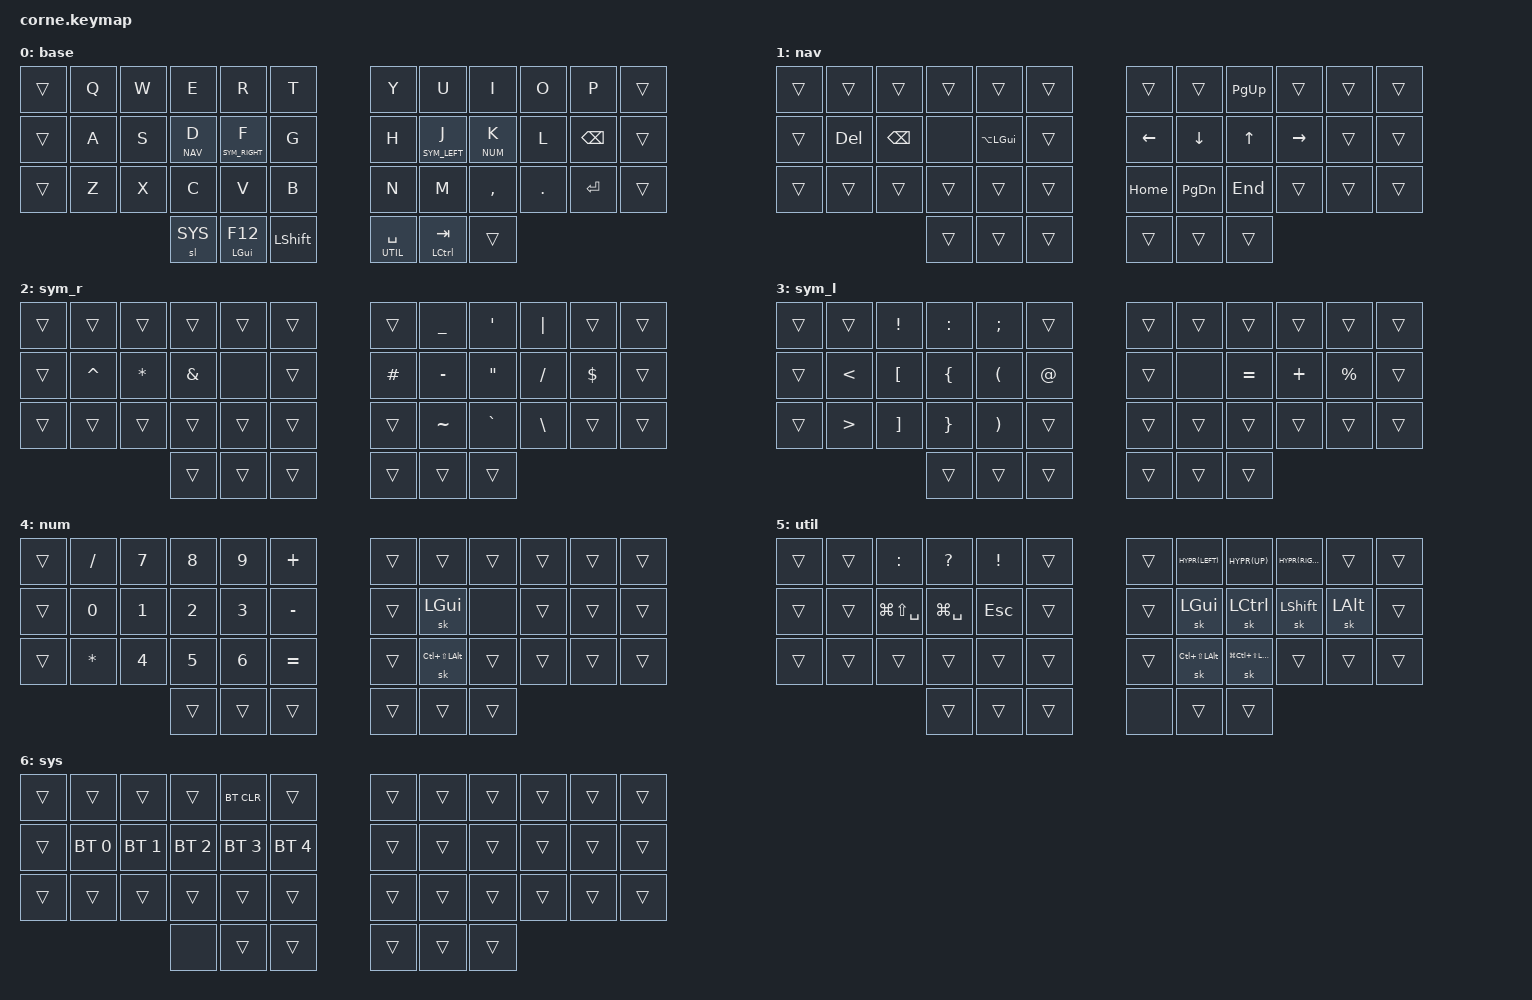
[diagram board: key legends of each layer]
/*
 * Copyright (c) 2020 The ZMK Contributors
 *
 * SPDX-License-Identifier: MIT
 */

#include <behaviors.dtsi>
#include <dt-bindings/zmk/keys.h>
#include <dt-bindings/zmk/bt.h>
#include <dt-bindings/zmk/outputs.h>

// Layer definitions
#define BASE 0
#define NAV 1
#define SYM_RIGHT 2
#define SYM_LEFT 3
#define NUM 4
#define UTIL 5
#define SYS 6

#define QUICK_TAP_MS 175

// QMK-like keycodes
#define _XXX &none
#define ____ &trans

#define _HYPR(kc) &kp LC(LS(LA(LG(kc))))
#define _MEH(kc) &kp LC(LS(LA(kc)))

#define _RAYCAST &kp LG(SPACE)
#define _1PASS &kp LG(LS(SPACE))

// Sticky mods - named explicitly here because I forget what they're are
#define _SK_MEH &sk LC(LS(LALT))
#define _SK_HYPR &sk LG(LC(LS(LALT)))

&mt {
  flavor = "balanced";
  tapping-term-ms = <280>;
  quick-tap-ms = <QUICK_TAP_MS>;
  global-quick-tap;
};

&sk {
  release-after-ms = <900>;
  quick-release;
};

&lt {
  flavor = "balanced";
  tapping-term-ms = <200>;
  quick-tap-ms = <QUICK_TAP_MS>;
};

/ {
	combos {
		compatible = "zmk,combos";

		// both right thumb keys
		combo_sys {
			timeout-ms = <200>;
			key-positions = <39 40>;
			bindings = <&mo SYS>;
		};
		// left index and middle finger
		combo_esc {
			timeout-ms = <50>;
			key-positions = <15 16>;
			bindings = <&kp ESC>;
		};
		// left middle and ring finger one row down
		combo_hypr_l {
			timeout-ms = <50>;
			key-positions = <26 27>;
			bindings = <&kp LG(LC(LS(LALT)))>;
		};
		// left index and middle finger one row down
		combo_meh_l {
			timeout-ms = <50>;
			key-positions = <27 28>;
			bindings = <&kp LC(LS(LALT))>;
		};
		// right index and middle finger one row down
		combo_meh_r {
			timeout-ms = <50>;
			key-positions = <31 32>;
			bindings = <&kp LC(LS(LALT))>;
		};
		// right middle and ring finger one row down
		combo_hypr_r {
			timeout-ms = <50>;
			key-positions = <32 33>;
			bindings = <&kp LG(LC(LS(LALT)))>;
		};
	};

  keymap {
    compatible = "zmk,keymap";

    base {
      display-name = "base";
      bindings = <
//        ┌──────┬───┬───┬──────────┬───────────────┬──────┐                        ┌───────────────┬───────────────┬──────────┬───┬──────┬──────┐
//        │ ____ │ Q │ W │    E     │       R       │  T   │                        │       Y       │       U       │    I     │ O │  P   │ ____ │
//        ├──────┼───┼───┼──────────┼───────────────┼──────┤                        ├───────────────┼───────────────┼──────────┼───┼──────┼──────┤
//        │ ____ │ A │ S │ lt NAV D │ lt SYM_rght F │  G   │                        │       H       │ lt SYM_left J │ lt NUM K │ L │ bspc │ ____ │
//        ├──────┼───┼───┼──────────┼───────────────┼──────┤                        ├───────────────┼───────────────┼──────────┼───┼──────┼──────┤
//        │ ____ │ Z │ X │    C     │       V       │  B   │                        │       N       │       M       │    ,     │ . │ ent  │ ____ │
//        └──────┴───┴───┴──────────┼───────────────┼──────┼──────┐   ┌─────────────┼───────────────┼───────────────┼──────────┴───┴──────┴──────┘
//                                  │    sl SYS     │ lgui │ lsft │   │ lt UTIL spc │ mt lctlTL tab │     ____      │
//                                  └───────────────┴──────┴──────┘   └─────────────┴───────────────┴───────────────┘
      ____   &kp Q   &kp W   &kp E       &kp R             &kp T                                        &kp Y          &kp U            &kp I       &kp O     &kp P       ____
      ____   &kp A   &kp S   &lt NAV D   &lt SYM_RIGHT F   &kp G                                        &kp H          &lt SYM_LEFT J   &lt NUM K   &kp L     &kp BSPC    ____
      ____   &kp Z   &kp X   &kp C       &kp V             &kp B                                        &kp N          &kp M            &kp COMMA   &kp DOT   &kp ENTER   ____
                                         &sl SYS           &mt LGUI F12   &kp LSHIFT       &lt UTIL SPACE   &mt LCTL TAB   ____
      >;
    };

    nav {
      display-name = "nav";
      bindings = <
//        ┌──────┬──────┬──────┬──────┬────────────┬──────┐                 ┌──────┬──────┬──────┬──────┬──────┬──────┐
//        │ ____ │ ____ │ ____ │ ____ │    ____    │ ____ │                 │ ____ │ ____ │ pgup │ ____ │ ____ │ ____ │
//        ├──────┼──────┼──────┼──────┼────────────┼──────┤                 ├──────┼──────┼──────┼──────┼──────┼──────┤
//        │ ____ │ del  │ bspc │ _XXX │ lalt(lgui) │ ____ │                 │ left │ down │  up  │ rght │ ____ │ ____ │
//        ├──────┼──────┼──────┼──────┼────────────┼──────┤                 ├──────┼──────┼──────┼──────┼──────┼──────┤
//        │ ____ │ ____ │ ____ │ ____ │    ____    │ ____ │                 │ home │ pgdn │ end  │ ____ │ ____ │ ____ │
//        └──────┴──────┴──────┴──────┼────────────┼──────┼──────┐   ┌──────┼──────┼──────┼──────┴──────┴──────┴──────┘
//                                    │    ____    │ ____ │ ____ │   │ ____ │ ____ │ ____ │
//                                    └────────────┴──────┴──────┘   └──────┴──────┴──────┘
      ____   ____      ____       ____   ____           ____                     ____       ____        &kp PG_UP   ____        ____   ____
      ____   &kp DEL   &kp BSPC   _XXX   &kp LA(LGUI)   ____                     &kp LEFT   &kp DOWN    &kp UP      &kp RIGHT   ____   ____
      ____   ____      ____       ____   ____           ____                     &kp HOME   &kp PG_DN   &kp END     ____        ____   ____
                                         ____           ____   ____       ____   ____       ____
      >;
    };

    sym_right {
      display-name = "sym_r";
      bindings = <
//        ┌──────┬──────┬──────┬──────┬──────┬──────┐                 ┌──────┬──────┬───┬───┬──────┬──────┐
//        │ ____ │ ____ │ ____ │ ____ │ ____ │ ____ │                 │ ____ │  _   │ ' │ | │ ____ │ ____ │
//        ├──────┼──────┼──────┼──────┼──────┼──────┤                 ├──────┼──────┼───┼───┼──────┼──────┤
//        │ ____ │  ^   │  *   │  &   │ _XXX │ ____ │                 │  #   │  -   │ " │ / │  $   │ ____ │
//        ├──────┼──────┼──────┼──────┼──────┼──────┤                 ├──────┼──────┼───┼───┼──────┼──────┤
//        │ ____ │ ____ │ ____ │ ____ │ ____ │ ____ │                 │ ____ │  ~   │ ` │ \ │ ____ │ ____ │
//        └──────┴──────┴──────┴──────┼──────┼──────┼──────┐   ┌──────┼──────┼──────┼───┴───┴──────┴──────┘
//                                    │ ____ │ ____ │ ____ │   │ ____ │ ____ │ ____ │
//                                    └──────┴──────┴──────┘   └──────┴──────┴──────┘
      ____   ____        ____       ____       ____   ____                     ____       &kp UNDER   &kp SQT     &kp PIPE   ____         ____
      ____   &kp CARET   &kp STAR   &kp AMPS   _XXX   ____                     &kp HASH   &kp MINUS   &kp DQT     &kp FSLH   &kp DOLLAR   ____
      ____   ____        ____       ____       ____   ____                     ____       &kp TILDE   &kp GRAVE   &kp BSLH   ____         ____
                                               ____   ____   ____       ____   ____       ____
      >;
    };

    sym_left {
      display-name = "sym_l";
      bindings = <
//        ┌──────┬──────┬───┬───┬──────┬──────┐                 ┌──────┬──────┬──────┬──────┬──────┬──────┐
//        │ ____ │ ____ │ ! │ : │  ;   │ ____ │                 │ ____ │ ____ │ ____ │ ____ │ ____ │ ____ │
//        ├──────┼──────┼───┼───┼──────┼──────┤                 ├──────┼──────┼──────┼──────┼──────┼──────┤
//        │ ____ │  <   │ [ │ { │  (   │  @   │                 │ ____ │ _XXX │ EQL  │  +   │  %   │ ____ │
//        ├──────┼──────┼───┼───┼──────┼──────┤                 ├──────┼──────┼──────┼──────┼──────┼──────┤
//        │ ____ │  >   │ ] │ } │  )   │ ____ │                 │ ____ │ ____ │ ____ │ ____ │ ____ │ ____ │
//        └──────┴──────┴───┴───┼──────┼──────┼──────┐   ┌──────┼──────┼──────┼──────┴──────┴──────┴──────┘
//                              │ ____ │ ____ │ ____ │   │ ____ │ ____ │ ____ │
//                              └──────┴──────┴──────┘   └──────┴──────┴──────┘
      ____   ____     &kp EXCL   &kp COLON   &kp SEMI   ____                       ____   ____   ____      ____       ____          ____
      ____   &kp LT   &kp LBKT   &kp LBRC    &kp LPAR   &kp AT                     ____   _XXX   &kp EQL   &kp PLUS   &kp PERCENT   ____
      ____   &kp GT   &kp RBKT   &kp RBRC    &kp RPAR   ____                       ____   ____   ____      ____       ____          ____
                                             ____       ____     ____       ____   ____   ____
      >;
    };

    num {
      display-name = "num";
      bindings = <
//        ┌──────┬───┬───┬───┬──────┬──────┐                 ┌──────┬──────────────────────┬──────┬──────┬──────┬──────┐
//        │ ____ │ / │ 7 │ 8 │  9   │  +   │                 │ ____ │         ____         │ ____ │ ____ │ ____ │ ____ │
//        ├──────┼───┼───┼───┼──────┼──────┤                 ├──────┼──────────────────────┼──────┼──────┼──────┼──────┤
//        │ ____ │ 0 │ 1 │ 2 │  3   │  -   │                 │ ____ │       &sk lgui       │ _XXX │ ____ │ ____ │ ____ │
//        ├──────┼───┼───┼───┼──────┼──────┤                 ├──────┼──────────────────────┼──────┼──────┼──────┼──────┤
//        │ ____ │ * │ 4 │ 5 │  6   │ EQL  │                 │ ____ │ &sk lctl(lsft(lalt)) │ ____ │ ____ │ ____ │ ____ │
//        └──────┴───┴───┴───┼──────┼──────┼──────┐   ┌──────┼──────┼──────────────────────┼──────┴──────┴──────┴──────┘
//                           │ ____ │ ____ │ ____ │   │ ____ │ ____ │         ____         │
//                           └──────┴──────┴──────┘   └──────┴──────┴──────────────────────┘
      ____   &kp FSLH   &kp N7   &kp N8   &kp N9   &kp PLUS                      ____   ____               ____   ____   ____   ____
      ____   &kp N0     &kp N1   &kp N2   &kp N3   &kp MINUS                     ____   &sk LGUI           _XXX   ____   ____   ____
      ____   &kp STAR   &kp N4   &kp N5   &kp N6   &kp EQL                       ____   &sk LC(LS(LALT))   ____   ____   ____   ____
                                          ____     ____        ____       ____   ____   ____
      >;
    };

    util {
      display-name = "util";
      bindings = <
//        ┌──────┬──────┬────────┬────────────┬──────┬──────┐                 ┌──────┬─────────────┬────────────┬─────────────┬──────────┬──────┐
//        │ ____ │ ____ │   :    │     ?      │  !   │ ____ │                 │ ____ │ _HYPR(left) │ _HYPR(up)  │ _HYPR(rght) │   ____   │ ____ │
//        ├──────┼──────┼────────┼────────────┼──────┼──────┤                 ├──────┼─────────────┼────────────┼─────────────┼──────────┼──────┤
//        │ ____ │ ____ │ _1PASS │ _raltYCAST │ esc  │ ____ │                 │ ____ │  &sk lgui   │ &sk lctlTL │  &sk lsft   │ &sk lalt │ ____ │
//        ├──────┼──────┼────────┼────────────┼──────┼──────┤                 ├──────┼─────────────┼────────────┼─────────────┼──────────┼──────┤
//        │ ____ │ ____ │  ____  │    ____    │ ____ │ ____ │                 │ ____ │   _SK_MEH   │  _SK_HYPR  │    ____     │   ____   │ ____ │
//        └──────┴──────┴────────┴────────────┼──────┼──────┼──────┐   ┌──────┼──────┼─────────────┼────────────┴─────────────┴──────────┴──────┘
//                                            │ ____ │ ____ │ ____ │   │ _XXX │ ____ │    ____     │
//                                            └──────┴──────┴──────┘   └──────┴──────┴─────────────┘
      ____   ____   &kp COLON   &kp QMARK   &kp EXCL   ____                     ____   _HYPR(LEFT)   _HYPR(UP)   _HYPR(RIGHT)   ____       ____
      ____   ____   _1PASS      _RAYCAST    &kp ESC    ____                     ____   &sk LGUI      &sk LCTL    &sk LSHIFT     &sk LALT   ____
      ____   ____   ____        ____        ____       ____                     ____   _SK_MEH       _SK_HYPR    ____           ____       ____
                                            ____       ____   ____       _XXX   ____   ____
      >;
    };

    sys {
      display-name = "sys";
      bindings = <
//        ┌──────┬──────────┬──────────┬──────────┬──────────┬──────────┐                 ┌──────┬──────┬──────┬──────┬──────┬──────┐
//        │ ____ │   ____   │   ____   │   ____   │  bt_clr  │   ____   │                 │ ____ │ ____ │ ____ │ ____ │ ____ │ ____ │
//        ├──────┼──────────┼──────────┼──────────┼──────────┼──────────┤                 ├──────┼──────┼──────┼──────┼──────┼──────┤
//        │ ____ │ bt_sel 0 │ bt_sel 1 │ bt_sel 2 │ bt_sel 3 │ bt_sel 4 │                 │ ____ │ ____ │ ____ │ ____ │ ____ │ ____ │
//        ├──────┼──────────┼──────────┼──────────┼──────────┼──────────┤                 ├──────┼──────┼──────┼──────┼──────┼──────┤
//        │ ____ │   ____   │   ____   │   ____   │   ____   │   ____   │                 │ ____ │ ____ │ ____ │ ____ │ ____ │ ____ │
//        └──────┴──────────┴──────────┴──────────┼──────────┼──────────┼──────┐   ┌──────┼──────┼──────┼──────┴──────┴──────┴──────┘
//                                                │   _XXX   │   ____   │ ____ │   │ ____ │ ____ │ ____ │
//                                                └──────────┴──────────┴──────┘   └──────┴──────┴──────┘
      ____   ____           ____           ____           &bt BT_CLR     ____                             ____   ____   ____   ____   ____   ____
      ____   &bt BT_SEL 0   &bt BT_SEL 1   &bt BT_SEL 2   &bt BT_SEL 3   &bt BT_SEL 4                     ____   ____   ____   ____   ____   ____
      ____   ____           ____           ____           ____           ____                             ____   ____   ____   ____   ____   ____
                                                          _XXX           ____           ____       ____   ____   ____
      >;
    };
  };
};
